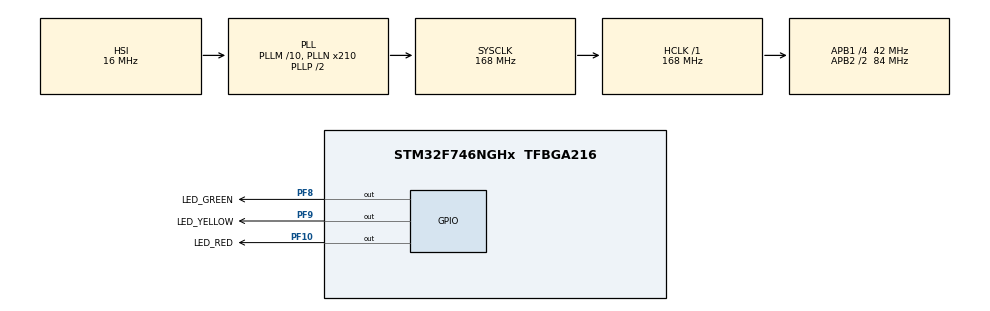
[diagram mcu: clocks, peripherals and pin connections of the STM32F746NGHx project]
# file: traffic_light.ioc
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Mcu.Family=STM32F7
Mcu.Name=STM32F746NGHx
Mcu.Package=TFBGA216
NVIC.PriorityGroup=NVIC_PRIORITYGROUP_4
NVIC.TIM8_TRG_COM_TIM14_IRQn=true\:0\:0\:false\:false\:true\:false\:true
NVIC.TimeBase=TIM8_TRG_COM_TIM14_IRQn
NVIC.TimeBaseIP=TIM14
PA13.Mode=Serial_Wire
PA13.Signal=SYS_JTMS-SWDIO
PA14.Mode=Serial_Wire
PA14.Signal=SYS_JTCK-SWCLK
PC14/OSC32_IN.Mode=LSE-External-Oscillator
PC14/OSC32_IN.Signal=RCC_OSC32_IN
PC15/OSC32_OUT.Mode=LSE-External-Oscillator
PC15/OSC32_OUT.Signal=RCC_OSC32_OUT
PF10.GPIO_Label=LED_RED
PF10.Signal=GPIO_Output
PF8.GPIO_Label=LED_GREEN
PF8.Signal=GPIO_Output
PF9.GPIO_Label=LED_YELLOW
PF9.Signal=GPIO_Output
PH0/OSC_IN.Mode=HSE-External-Clock-Source
PH0/OSC_IN.Signal=RCC_OSC_IN
PH1/OSC_OUT.Mode=HSE-External-Clock-Source
PH1/OSC_OUT.Signal=RCC_OSC_OUT
ProjectManager.HeapSize=0x200
ProjectManager.StackSize=0x400
ProjectManager.TargetToolchain=STM32CubeIDE
RCC.AHBFreq_Value=168000000
RCC.APB1CLKDivider=RCC_HCLK_DIV4
RCC.APB1Freq_Value=42000000
RCC.APB1TimFreq_Value=84000000
RCC.APB2CLKDivider=RCC_HCLK_DIV2
RCC.APB2Freq_Value=84000000
RCC.APB2TimFreq_Value=168000000
RCC.CortexFreq_Value=168000000
RCC.HCLKFreq_Value=168000000
RCC.HSE_VALUE=25000000
RCC.HSI_VALUE=16000000
RCC.PLLM=10
RCC.PLLN=210
RCC.PLLSourceVirtual=RCC_PLLSOURCE_HSI
RCC.SYSCLKFreq_VALUE=168000000
RCC.SYSCLKSource=RCC_SYSCLKSOURCE_PLLCLK
RCC.USBFreq_Value=168000000
RCC.VCOOutputFreq_Value=336000000
TIM2.Channel-Output\ Compare1\ No\ Output=TIM_CHANNEL_1
TIM2.Period=40000-1
TIM2.Prescaler=8400-1
VP_SYS_VS_tim14.Mode=TIM14
VP_TIM2_VS_no_output1.Mode=Output Compare1 No Output
board=STM32F746G-DISCO

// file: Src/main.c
/* USER CODE BEGIN Header */
/**
  ******************************************************************************
  * @file           : main.c
  * @brief          : Main program body
  ******************************************************************************
  * @attention
  *
  * <h2><center>&copy; Copyright (c) 2019 STMicroelectronics.
  * All rights reserved.</center></h2>
  *
  * This software component is licensed by ST under BSD 3-Clause license,
  * the "License"; You may not use this file except in compliance with the
  * License. You may obtain a copy of the License at:
  *                        opensource.org/licenses/BSD-3-Clause
  *
  ******************************************************************************
  */
/* USER CODE END Header */

#include "main.h"

TIM_HandleTypeDef htim2;

void SystemClock_Config(void);
static void MX_GPIO_Init(void);
static void MX_TIM2_Init(void);

int main(void)
{

  /* MCU Configuration--------------------------------------------------------*/

  /* Reset of all peripherals, Initializes the Flash interface and the Systick. */
  HAL_Init();

  /* Configure the system clock */
  SystemClock_Config();

  /* Initialize all configured peripherals */
  MX_GPIO_Init();
  MX_TIM2_Init();
  /* USER CODE BEGIN 2 */
  HAL_TIM_OC_Start(&htim2, TIM_CHANNEL_1);
  uint16_t timer_value = 0;
  /* USER CODE END 2 */

  /* Infinite loop */
  /* USER CODE BEGIN WHILE */
  while (1)
  {
	  timer_value = __HAL_TIM_GET_COUNTER(&htim2);
	  if(timer_value < 2000) {
		  HAL_GPIO_WritePin(LED_GREEN_GPIO_Port, LED_GREEN_Pin, 1);
	  } else if(timer_value > 2000 && timer_value < 4000) {
		  HAL_GPIO_WritePin(LED_GREEN_GPIO_Port, LED_GREEN_Pin, 0);
		  HAL_GPIO_WritePin(LED_YELLOW_GPIO_Port, LED_YELLOW_Pin, 1);
	  } else if (timer_value > 4000 && timer_value < 6000) {
		  HAL_GPIO_WritePin(LED_YELLOW_GPIO_Port, LED_YELLOW_Pin, 0);
		  HAL_GPIO_WritePin(LED_RED_GPIO_Port, LED_RED_Pin, 1);
	  } else if (timer_value > 4000 && timer_value < 6000) {
		 HAL_GPIO_WritePin(LED_YELLOW_GPIO_Port, LED_YELLOW_Pin, 1);
	  }
    /* USER CODE END WHILE */

  }
}

void SystemClock_Config(void)
{
  RCC_OscInitTypeDef RCC_OscInitStruct = {0};
  RCC_ClkInitTypeDef RCC_ClkInitStruct = {0};

  /** Configure LSE Drive Capability
  */
  HAL_PWR_EnableBkUpAccess();
  /** Configure the main internal regulator output voltage
  */
  __HAL_RCC_PWR_CLK_ENABLE();
  __HAL_PWR_VOLTAGESCALING_CONFIG(PWR_REGULATOR_VOLTAGE_SCALE2);
  /** Initializes the CPU, AHB and APB busses clocks
  */
  RCC_OscInitStruct.OscillatorType = RCC_OSCILLATORTYPE_HSI;
  RCC_OscInitStruct.HSIState = RCC_HSI_ON;
  RCC_OscInitStruct.HSICalibrationValue = RCC_HSICALIBRATION_DEFAULT;
  RCC_OscInitStruct.PLL.PLLState = RCC_PLL_ON;
  RCC_OscInitStruct.PLL.PLLSource = RCC_PLLSOURCE_HSI;
  RCC_OscInitStruct.PLL.PLLM = 10;
  RCC_OscInitStruct.PLL.PLLN = 210;
  RCC_OscInitStruct.PLL.PLLP = RCC_PLLP_DIV2;
  RCC_OscInitStruct.PLL.PLLQ = 2;
  if (HAL_RCC_OscConfig(&RCC_OscInitStruct) != HAL_OK)
  {
    Error_Handler();
  }
  /** Initializes the CPU, AHB and APB busses clocks
  */
  RCC_ClkInitStruct.ClockType = RCC_CLOCKTYPE_HCLK|RCC_CLOCKTYPE_SYSCLK
                              |RCC_CLOCKTYPE_PCLK1|RCC_CLOCKTYPE_PCLK2;
  RCC_ClkInitStruct.SYSCLKSource = RCC_SYSCLKSOURCE_PLLCLK;
  RCC_ClkInitStruct.AHBCLKDivider = RCC_SYSCLK_DIV1;
  RCC_ClkInitStruct.APB1CLKDivider = RCC_HCLK_DIV4;
  RCC_ClkInitStruct.APB2CLKDivider = RCC_HCLK_DIV2;

  if (HAL_RCC_ClockConfig(&RCC_ClkInitStruct, FLASH_LATENCY_5) != HAL_OK)
  {
    Error_Handler();
  }
}

static void MX_TIM2_Init(void)
{

  TIM_MasterConfigTypeDef sMasterConfig = {0};
  TIM_OC_InitTypeDef sConfigOC = {0};

  htim2.Instance = TIM2;
  htim2.Init.Prescaler = 8400-1;
  htim2.Init.CounterMode = TIM_COUNTERMODE_UP;
  htim2.Init.Period = 40000-1;
  htim2.Init.ClockDivision = TIM_CLOCKDIVISION_DIV1;
  htim2.Init.AutoReloadPreload = TIM_AUTORELOAD_PRELOAD_DISABLE;
  if (HAL_TIM_OC_Init(&htim2) != HAL_OK)
  {
    Error_Handler();
  }
  sMasterConfig.MasterOutputTrigger = TIM_TRGO_RESET;
  sMasterConfig.MasterSlaveMode = TIM_MASTERSLAVEMODE_DISABLE;
  if (HAL_TIMEx_MasterConfigSynchronization(&htim2, &sMasterConfig) != HAL_OK)
  {
    Error_Handler();
  }
  sConfigOC.OCMode = TIM_OCMODE_TIMING;
  sConfigOC.Pulse = 0;
  sConfigOC.OCPolarity = TIM_OCPOLARITY_HIGH;
  sConfigOC.OCFastMode = TIM_OCFAST_DISABLE;
  if (HAL_TIM_OC_ConfigChannel(&htim2, &sConfigOC, TIM_CHANNEL_1) != HAL_OK)
  {
    Error_Handler();
  }

}

static void MX_GPIO_Init(void)
{
  GPIO_InitTypeDef GPIO_InitStruct = {0};

  /* GPIO Ports Clock Enable */
  __HAL_RCC_GPIOA_CLK_ENABLE();
  __HAL_RCC_GPIOC_CLK_ENABLE();
  __HAL_RCC_GPIOH_CLK_ENABLE();
  __HAL_RCC_GPIOF_CLK_ENABLE();

  /*Configure GPIO pin Output Level */
  HAL_GPIO_WritePin(GPIOF, LED_RED_Pin|LED_YELLOW_Pin|LED_GREEN_Pin, GPIO_PIN_RESET);

  /*Configure GPIO pins : LED_RED_Pin LED_YELLOW_Pin LED_GREEN_Pin */
  GPIO_InitStruct.Pin = LED_RED_Pin|LED_YELLOW_Pin|LED_GREEN_Pin;
  GPIO_InitStruct.Mode = GPIO_MODE_OUTPUT_PP;
  GPIO_InitStruct.Pull = GPIO_NOPULL;
  GPIO_InitStruct.Speed = GPIO_SPEED_FREQ_LOW;
  HAL_GPIO_Init(GPIOF, &GPIO_InitStruct);

}

void HAL_TIM_PeriodElapsedCallback(TIM_HandleTypeDef *htim)
{
  if (htim->Instance == TIM14) {
    HAL_IncTick();
  }
}

void Error_Handler(void)
{
}

/************************ (C) COPYRIGHT STMicroelectronics *****END OF FILE****/
